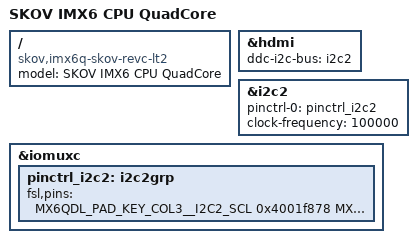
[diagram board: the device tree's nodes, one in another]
// SPDX-License-Identifier: (GPL-2.0 OR MIT)
//
// Copyright (C) 2020 Pengutronix, Ulrich Oelmann <kernel@pengutronix.de>

/dts-v1/;
#include "imx6q.dtsi"
#include "imx6qdl-skov-cpu.dtsi"
#include "imx6qdl-skov-cpu-revc.dtsi"
#include "imx6qdl-skov-revc-lt2.dtsi"

/ {
	model = "SKOV IMX6 CPU QuadCore";
	compatible = "skov,imx6q-skov-revc-lt2", "fsl,imx6q";
};

&hdmi {
	ddc-i2c-bus = <&i2c2>;
	status = "okay";
};

&i2c2 {
	pinctrl-names = "default";
	pinctrl-0 = <&pinctrl_i2c2>;
	clock-frequency = <100000>;
	status = "okay";
};

&iomuxc {
	pinctrl_i2c2: i2c2grp {
		fsl,pins = <
			/* internal 22 k pull up required */
			MX6QDL_PAD_KEY_COL3__I2C2_SCL		0x4001f878
			/* internal 22 k pull up required */
			MX6QDL_PAD_KEY_ROW3__I2C2_SDA		0x4001f878
		>;
	};
};
